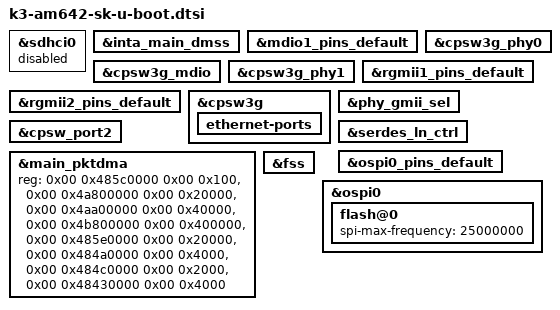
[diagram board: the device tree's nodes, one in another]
// SPDX-License-Identifier: GPL-2.0
/*
 * Copyright (C) 2021 Texas Instruments Incorporated - https://www.ti.com/
 */

#include "k3-am64x-binman.dtsi"
#include "k3-am642-u-boot.dtsi"

&sdhci0 {
	status = "disabled";
};

&inta_main_dmss {
	bootph-all;
};

&mdio1_pins_default {
	bootph-all;
};

&cpsw3g_mdio {
	bootph-all;
};

&cpsw3g_phy0 {
	bootph-all;
};

&cpsw3g_phy1 {
	bootph-all;
};

&rgmii1_pins_default {
	bootph-all;
};

&rgmii2_pins_default {
	bootph-all;
};

&cpsw3g {
	bootph-all;

	ethernet-ports {
		bootph-all;
	};
};

&phy_gmii_sel {
	bootph-all;
};

&cpsw_port2 {
	bootph-all;
};

&main_pktdma {
	reg = <0x00 0x485c0000 0x00 0x100>,
	      <0x00 0x4a800000 0x00 0x20000>,
	      <0x00 0x4aa00000 0x00 0x40000>,
	      <0x00 0x4b800000 0x00 0x400000>,
	      <0x00 0x485e0000 0x00 0x20000>,
	      <0x00 0x484a0000 0x00 0x4000>,
	      <0x00 0x484c0000 0x00 0x2000>,
	      <0x00 0x48430000 0x00 0x4000>;
	reg-names = "gcfg", "rchanrt", "tchanrt", "ringrt", "cfg",
		    "tchan", "rchan", "rflow";
};

&rgmii1_pins_default {
	bootph-all;
};

&rgmii2_pins_default {
	bootph-all;
};

&mdio1_pins_default {
	bootph-all;
};

&cpsw3g_phy1 {
	bootph-all;
};

&serdes_ln_ctrl {
	bootph-all;
};

&ospi0_pins_default {
	bootph-all;
};

&fss {
	bootph-all;
};

&ospi0 {
 	bootph-all;

	flash@0 {
		bootph-all;
		spi-max-frequency = <25000000>;
	};
};
